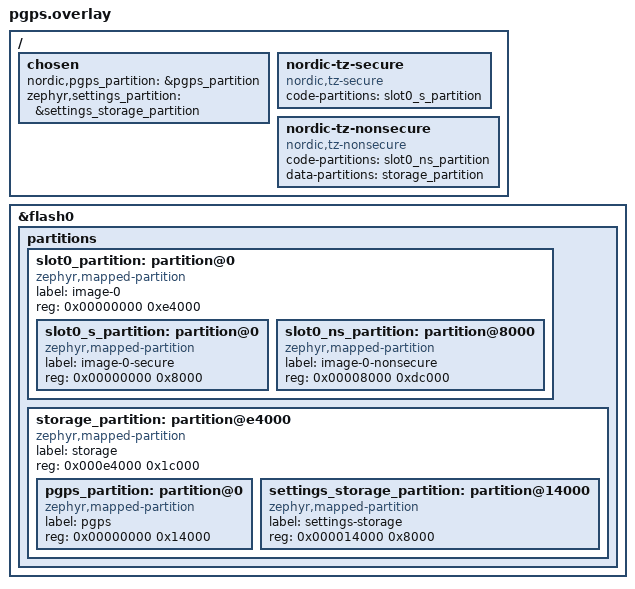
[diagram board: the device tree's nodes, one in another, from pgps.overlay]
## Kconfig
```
#
# Copyright (c) 2020 Nordic Semiconductor ASA
#
# SPDX-License-Identifier: LicenseRef-Nordic-5-Clause
#

menu "GNSS sample"

choice
	default GNSS_SAMPLE_MODE_CONTINUOUS
	prompt "Select GNSS operation mode"

config GNSS_SAMPLE_MODE_CONTINUOUS
	bool "Continuous tracking"

config GNSS_SAMPLE_MODE_PERIODIC
	bool "Periodic fixes"

config GNSS_SAMPLE_MODE_TTFF_TEST
	bool "Time-to-first-fix (TTFF) test mode"
	select GNSS_SAMPLE_NMEA_ONLY

endchoice

if GNSS_SAMPLE_MODE_PERIODIC

config GNSS_SAMPLE_PERIODIC_INTERVAL
	int "Fix interval for periodic fixes"
	range 10 65535
	default 120
	help
	  Fix interval (in seconds) for periodic fixes.

config GNSS_SAMPLE_PERIODIC_TIMEOUT
	int "Fix timeout for periodic fixes"
	range 0 65535
	default 120
	help
	  Fix timeout (in seconds) for periodic fixes.
	  If set to zero, GNSS is allowed to run indefinitely until a valid PVT estimate is produced.

endif # GNSS_SAMPLE_MODE_PERIODIC

if GNSS_SAMPLE_MODE_TTFF_TEST

config GNSS_SAMPLE_MODE_TTFF_TEST_COLD_START
	bool "Delete GNSS data before each start (cold start)"
	help
	  When enabled, deletes all stored data from GNSS to force a cold start every time GNSS is started.

config GNSS_SAMPLE_MODE_TTFF_TEST_INTERVAL
	int "Time to wait between TTFF tests in seconds"
	range 1 604800
	default 120

endif # GNSS_SAMPLE_MODE_TTFF_TEST

config GNSS_SAMPLE_NMEA_ONLY
	bool "Output only NMEA strings"
	help
	  Outputs only NMEA strings from the GNSS.

endmenu

choice
	default GNSS_SAMPLE_ASSISTANCE_NONE
	prompt "Select whether GNSS assistance is used or not"

config GNSS_SAMPLE_ASSISTANCE_NONE
	bool "Assistance not used"

config GNSS_SAMPLE_ASSISTANCE_NRF_CLOUD
	bool "Use nRF Cloud A-GNSS"
	select NRF_CLOUD
	select NRF_CLOUD_COAP
	imply NRF_CLOUD_AGNSS
	select MODEM_JWT
	select MODEM_INFO
	select DATE_TIME

config GNSS_SAMPLE_ASSISTANCE_SUPL
	bool "Use SUPL assistance"
	select SUPL_CLIENT_LIB

config GNSS_SAMPLE_ASSISTANCE_MINIMAL
	bool "Use factory almanac, LTE network time and MCC based location"
	select GNSS_SAMPLE_LTE_ON_DEMAND
	select SETTINGS
	select NVS
	select FLASH
	select FLASH_MAP

endchoice

if !GNSS_SAMPLE_ASSISTANCE_NONE

config GNSS_SAMPLE_LTE_ON_DEMAND
	bool "LTE is activated only when needed to fetch A-GNSS data"
	depends on !NRF_CLOUD_PGPS
	help
	  Activates LTE only when it is needed to fetch A-GNSS data. This is not supported when
	  P-GPS is enabled.

endif # !GNSS_SAMPLE_ASSISTANCE_NONE

if GNSS_SAMPLE_ASSISTANCE_NRF_CLOUD

configdefault COAP_CLIENT_BLOCK_SIZE
	default 1024

configdefault COAP_CLIENT_STACK_SIZE
	default 6144

configdefault COAP_CLIENT_THREAD_PRIORITY
	default 0

endif # GNSS_SAMPLE_ASSISTANCE_NRF_CLOUD

if GNSS_SAMPLE_ASSISTANCE_SUPL

config GNSS_SAMPLE_SUPL_HOSTNAME
	string "SUPL server hostname"
	help
	  SUPL server hostname.

config GNSS_SAMPLE_SUPL_PORT
	int "SUPL server port number"
	range 0 65535
	default 7275 if GNSS_SAMPLE_SUPL_SEC_TAG > 0
	default 7276
	help
	  SUPL server port number. The OMA UserPlane Location Protocol (ULP) port number is 7275,
	  but some servers are known to use port 7276 for non-TLS connections.

config GNSS_SAMPLE_SUPL_SEC_TAG
	int "Security tag for connection to the SUPL server"
	range 0 2147483667
	default 0
	help
	  Set a non-zero value to use TLS for connection to the SUPL server. When TLS is enabled,
	  a root CA certificate must be stored on the modem.

endif # GNSS_SAMPLE_ASSISTANCE_SUPL

if GNSS_SAMPLE_MODE_CONTINUOUS

choice
	default GNSS_SAMPLE_POWER_SAVING_DISABLED
	prompt "Select GNSS power saving mode (duty-cycling)"

config GNSS_SAMPLE_POWER_SAVING_DISABLED
	bool "No power saving"

config GNSS_SAMPLE_POWER_SAVING_MODERATE
	bool "Power saving without significant performance degradation"

config GNSS_SAMPLE_POWER_SAVING_HIGH
	bool "Power saving with acceptable performance degradation"

endchoice

endif # GNSS_SAMPLE_MODE_CONTINUOUS

config GNSS_SAMPLE_REFERENCE_LATITUDE
	string "Reference position latitude in decimal degrees"
	help
	  When set, the sample calculates the distance from the reference position for each fix.
	  Given in decimal degrees (DD), for example "61.500000".

config GNSS_SAMPLE_REFERENCE_LONGITUDE
	string "Reference position longitude in decimal degrees"
	help
	  When set, the sample calculates the distance from the reference position for each fix.
	  Given in decimal degrees (DD), for example "23.800000".

config GNSS_SAMPLE_LOW_ACCURACY
	bool "Allow low accuracy fixes"
	help
	  Allows fixes with lower accuracy.

if GNSS_SAMPLE_ASSISTANCE_MINIMAL && GNSS_SAMPLE_LOW_ACCURACY

config GNSS_SAMPLE_ASSISTANCE_REFERENCE_ALT
	int "Reference altitude for 3-sat first fix in meters"
	range -32767 32767
	default -32767
	help
	  Reference altitude for 3-sat first fix in meters above the reference ellipsoid surface.
	  The default value -32767 implies that reference altitude is not injected.

endif # GNSS_SAMPLE_ASSISTANCE_MINIMAL && GNSS_SAMPLE_LOW_ACCURACY

menu "Zephyr Kernel"
source "Kconfig.zephyr"
endmenu

module = GNSS_SAMPLE
module-str = GNSS sample
source "$(ZEPHYR_BASE)/subsys/logging/Kconfig.template.log_config"
```

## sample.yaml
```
sample:
  name: GNSS sample
tests:
  sample.cellular.gnss:
    sysbuild: true
    build_only: true
    integration_platforms:
      - nrf9151dk/nrf9151/ns
      - nrf9251dk/nrf9251/cpuapp
    platform_allow:
      - nrf9151dk/nrf9151/ns
      - nrf9251dk/nrf9251/cpuapp
    tags:
      - ci_build
      - sysbuild
      - ci_samples_cellular
  # Following configurations will be used by the positioning CI integration job to verify PRs
  sample.cellular.gnss.integration_config_positioning_agnss_nrfcloud_ltem_pvt:
    sysbuild: true
    build_only: true
    extra_configs:
      - CONFIG_LTE_NETWORK_MODE_LTE_M_GPS=y
      - CONFIG_LTE_NETWORK_MODE_NBIOT_GPS=n
      - CONFIG_GNSS_SAMPLE_LTE_ON_DEMAND=y
      - CONFIG_GNSS_SAMPLE_ASSISTANCE_NRF_CLOUD=y
      - CONFIG_GNSS_SAMPLE_NMEA_ONLY=n
      - CONFIG_GNSS_SAMPLE_MODE_PERIODIC=n
      - CONFIG_GNSS_SAMPLE_ASSISTANCE_MINIMAL=n
      - CONFIG_LTE_LC_EDRX_MODULE=y
      - CONFIG_LTE_EDRX_REQ=y
      - CONFIG_FPU=y
      - CONFIG_GNSS_SAMPLE_REFERENCE_LATITUDE="61.49375330"
      - CONFIG_GNSS_SAMPLE_REFERENCE_LONGITUDE="23.77588976"
      - CONFIG_MODEM_ANTENNA_GNSS_EXTERNAL=y
      - CONFIG_LOG_BUFFER_SIZE=2048
    extra_args:
      - gnss_SNIPPET="nrf91-modem-trace-uart"
      - SB_CONFIG_MERGED_HEX_FILES=y
    integration_platforms:
      - nrf9151dk/nrf9151/ns
    platform_allow:
      - nrf9151dk/nrf9151/ns
    tags:
      - ci_build
      - sysbuild
      - ci_samples_cellular
  sample.cellular.gnss.integration_config_positioning_agnss_nrfcloud_nbiot_nmea_lte_on:
    sysbuild: true
    build_only: true
    extra_configs:
      - CONFIG_LTE_NETWORK_MODE_LTE_M_GPS=n
      - CONFIG_LTE_NETWORK_MODE_NBIOT_GPS=y
      - CONFIG_GNSS_SAMPLE_LTE_ON_DEMAND=n
      - CONFIG_GNSS_SAMPLE_ASSISTANCE_NRF_CLOUD=y
      - CONFIG_GNSS_SAMPLE_NMEA_ONLY=y
      - CONFIG_GNSS_SAMPLE_MODE_PERIODIC=n
      - CONFIG_GNSS_SAMPLE_ASSISTANCE_MINIMAL=n
      - CONFIG_LTE_LC_EDRX_MODULE=y
      - CONFIG_LTE_EDRX_REQ=y
      - CONFIG_FPU=y
      - CONFIG_GNSS_SAMPLE_REFERENCE_LATITUDE="61.49375330"
      - CONFIG_GNSS_SAMPLE_REFERENCE_LONGITUDE="23.77588976"
      - CONFIG_MODEM_ANTENNA_GNSS_EXTERNAL=y
      - CONFIG_LOG_BUFFER_SIZE=2048
    extra_args:
      - gnss_SNIPPET="nrf91-modem-trace-uart"
      - SB_CONFIG_MERGED_HEX_FILES=y
    integration_platforms:
      - nrf9151dk/nrf9151/ns
    platform_allow:
      - nrf9151dk/nrf9151/ns
    tags:
      - ci_build
      - sysbuild
      - ci_samples_cellular
  sample.cellular.gnss.integration_config_positioning_pgps_nrfcloud_ltem_nmea:
    sysbuild: true
    build_only: true
    extra_configs:
      - CONFIG_LTE_NETWORK_MODE_LTE_M_GPS=y
      - CONFIG_LTE_NETWORK_MODE_NBIOT_GPS=n
      - CONFIG_GNSS_SAMPLE_LTE_ON_DEMAND=n
      - CONFIG_GNSS_SAMPLE_ASSISTANCE_NRF_CLOUD=n
      - CONFIG_GNSS_SAMPLE_NMEA_ONLY=y
      - CONFIG_GNSS_SAMPLE_MODE_PERIODIC=n
      - CONFIG_GNSS_SAMPLE_ASSISTANCE_MINIMAL=n
      - CONFIG_LTE_EDRX_REQ=n
      - CONFIG_FPU=y
      - CONFIG_GNSS_SAMPLE_REFERENCE_LATITUDE="61.49375330"
      - CONFIG_GNSS_SAMPLE_REFERENCE_LONGITUDE="23.77588976"
      - CONFIG_MODEM_ANTENNA_GNSS_EXTERNAL=y
      - CONFIG_LOG_BUFFER_SIZE=2048
    extra_args:
      - EXTRA_CONF_FILE=pgps.conf
      - EXTRA_DTC_OVERLAY_FILE=pgps.overlay
      - gnss_SNIPPET="nrf91-modem-trace-uart"
      - SB_CONFIG_MERGED_HEX_FILES=y
    integration_platforms:
      - nrf9151dk/nrf9151/ns
    platform_allow:
      - nrf9151dk/nrf9151/ns
    tags:
      - ci_build
      - sysbuild
      - ci_samples_cellular
  sample.cellular.gnss.integration_config_positioning_gnss_ltem_pvt:
    sysbuild: true
    build_only: true
    extra_configs:
      - CONFIG_LTE_NETWORK_MODE_LTE_M_GPS=y
      - CONFIG_LTE_NETWORK_MODE_NBIOT_GPS=n
      - CONFIG_GNSS_SAMPLE_LTE_ON_DEMAND=n
      - CONFIG_GNSS_SAMPLE_ASSISTANCE_NRF_CLOUD=n
      - CONFIG_GNSS_SAMPLE_NMEA_ONLY=n
      - CONFIG_GNSS_SAMPLE_MODE_PERIODIC=n
      - CONFIG_GNSS_SAMPLE_ASSISTANCE_MINIMAL=n
      - CONFIG_LTE_LC_EDRX_MODULE=y
      - CONFIG_LTE_EDRX_REQ=y
      - CONFIG_FPU=y
      - CONFIG_GNSS_SAMPLE_REFERENCE_LATITUDE="61.49375330"
      - CONFIG_GNSS_SAMPLE_REFERENCE_LONGITUDE="23.77588976"
      - CONFIG_MODEM_ANTENNA_GNSS_EXTERNAL=y
      - CONFIG_LOG_BUFFER_SIZE=2048
    extra_args:
      - gnss_SNIPPET="nrf91-modem-trace-uart"
      - SB_CONFIG_MERGED_HEX_FILES=y
    integration_platforms:
      - nrf9151dk/nrf9151/ns
    platform_allow:
      - nrf9151dk/nrf9151/ns
    tags:
      - ci_build
      - sysbuild
      - ci_samples_cellular
```

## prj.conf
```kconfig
#
# Copyright (c) 2019 Nordic Semiconductor ASA
#
# SPDX-License-Identifier: LicenseRef-Nordic-5-Clause
#

# TF-M config
CONFIG_TFM_PROFILE_TYPE_MINIMAL=y

# General
CONFIG_FPU=y
CONFIG_NRF_MODEM_LIB=y
CONFIG_STDOUT_CONSOLE=y
CONFIG_UART_INTERRUPT_DRIVEN=y
CONFIG_PICOLIBC_IO_FLOAT=y
CONFIG_LOG=y
CONFIG_LOG_MODE_IMMEDIATE=y

# GNSS sample
# Enable to use nRF Cloud A-GNSS
CONFIG_GNSS_SAMPLE_ASSISTANCE_NRF_CLOUD=n

# LTE Link Control
CONFIG_LTE_LINK_CONTROL=y
CONFIG_LTE_LC_PSM_MODULE=y
CONFIG_LTE_PSM_REQ=y
# PSM requested periodic TAU 8 hours
CONFIG_LTE_PSM_REQ_RPTAU="00101000"
# PSM requested active time 6 seconds
CONFIG_LTE_PSM_REQ_RAT="00000011"

# AT Host library - Used to send AT commands directy from an UART terminal and to allow
#		    integration with nRF Connect for Desktop LTE Link monitor application.
CONFIG_AT_HOST_LIBRARY=y

# Networking
CONFIG_NETWORKING=y
CONFIG_NET_SOCKETS_OFFLOAD=y
CONFIG_NET_SOCKETS=y
# Disable native network stack to save some memory
CONFIG_NET_NATIVE=n

# Memory and stack configuration
CONFIG_HEAP_MEM_POOL_SIZE=2048
CONFIG_MAIN_STACK_SIZE=4096
CONFIG_SYSTEM_WORKQUEUE_STACK_SIZE=1536
```

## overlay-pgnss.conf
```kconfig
#
# Copyright (c) 2021 Nordic Semiconductor ASA
#
# SPDX-License-Identifier: LicenseRef-Nordic-5-Clause
#

# PGNSS overlay configuration

# Enable nRF Cloud assistance for GNSS sample
CONFIG_GNSS_SAMPLE_ASSISTANCE_NRF_CLOUD=y

# PGNSS
CONFIG_NRF_CLOUD_PGNSS=y
CONFIG_NRF_CLOUD_PGNSS_REPLACEMENT_THRESHOLD=4

# PGNSS downloads over CoAP require larger option values than the default.
CONFIG_COAP_EXTENDED_OPTIONS_LEN_VALUE=80

# Disable A-GNSS, comment this if you want to use both A-GNSS and PGNSS at the same time
CONFIG_NRF_CLOUD_AGNSS=n

# Storage for PGNSS
CONFIG_STREAM_FLASH=y
CONFIG_FLASH=y
CONFIG_FLASH_PAGE_LAYOUT=y
CONFIG_FLASH_MAP=y
CONFIG_FCB=y
CONFIG_SETTINGS=y
CONFIG_SETTINGS_FCB=y
CONFIG_MPU_ALLOW_FLASH_WRITE=y

# PGNSS needs more heap
CONFIG_HEAP_MEM_POOL_SIZE=8192

# Download Client - used by PGNSS
CONFIG_DOWNLOADER=y
CONFIG_DOWNLOADER_STACK_SIZE=1280
CONFIG_DOWNLOADER_MAX_HOSTNAME_SIZE=128
```

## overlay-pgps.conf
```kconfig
#
# Copyright (c) 2021 Nordic Semiconductor ASA
#
# SPDX-License-Identifier: LicenseRef-Nordic-5-Clause
#

# P-GPS overlay configuration

# Enable nRF Cloud assistance for GNSS sample
CONFIG_GNSS_SAMPLE_ASSISTANCE_NRF_CLOUD=y

# P-GPS
CONFIG_NRF_CLOUD_PGPS=y
CONFIG_NRF_CLOUD_PGPS_REPLACEMENT_THRESHOLD=4

# P-GPS downloads over CoAP require larger option values than the default.
CONFIG_COAP_EXTENDED_OPTIONS_LEN_VALUE=80

# Disable A-GNSS, comment this if you want to use both A-GNSS and P-GPS at the same time
CONFIG_NRF_CLOUD_AGNSS=n

# Storage for P-GPS
CONFIG_STREAM_FLASH=y
CONFIG_FLASH=y
CONFIG_FLASH_PAGE_LAYOUT=y
CONFIG_FLASH_MAP=y
CONFIG_FCB=y
CONFIG_SETTINGS=y
CONFIG_SETTINGS_FCB=y
CONFIG_MPU_ALLOW_FLASH_WRITE=y

# P-GPS needs more heap
CONFIG_HEAP_MEM_POOL_SIZE=8192

# Download Client - used by PGPS
CONFIG_DOWNLOADER=y
CONFIG_DOWNLOADER_STACK_SIZE=1280
CONFIG_DOWNLOADER_MAX_HOSTNAME_SIZE=128
```

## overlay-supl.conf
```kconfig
#
# Copyright (c) 2023 Nordic Semiconductor ASA
#
# SPDX-License-Identifier: LicenseRef-Nordic-5-Clause
#

# SUPL overlay configuration

# Enable SUPL assistance for GNSS sample
CONFIG_GNSS_SAMPLE_ASSISTANCE_SUPL=y

# SUPL client library requires that the newlib C library is used
CONFIG_NEWLIB_LIBC=y
CONFIG_NEWLIB_LIBC_FLOAT_PRINTF=y
```

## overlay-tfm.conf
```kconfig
#
# Copyright (c) 2019 Nordic Semiconductor ASA
#
# SPDX-License-Identifier: LicenseRef-Nordic-5-Clause
#

# TF-M config. Only the ``*/ns`` board targets build TF-M, so the TFM_PROFILE
# choice does not exist for board targets that run without it.
CONFIG_TFM_PROFILE_TYPE_MINIMAL=y
```

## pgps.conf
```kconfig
#
# Copyright (c) 2021 Nordic Semiconductor ASA
#
# SPDX-License-Identifier: LicenseRef-Nordic-5-Clause
#

# P-GPS overlay configuration

# Enable nRF Cloud assistance for GNSS sample
CONFIG_GNSS_SAMPLE_ASSISTANCE_NRF_CLOUD=y

# P-GPS
CONFIG_NRF_CLOUD_PGPS=y
CONFIG_NRF_CLOUD_PGPS_REPLACEMENT_THRESHOLD=4

# P-GPS downloads over CoAP require larger option values than the default.
CONFIG_COAP_EXTENDED_OPTIONS_LEN_VALUE=80

# Disable A-GNSS, comment this if you want to use both A-GNSS and P-GPS at the same time
CONFIG_NRF_CLOUD_AGNSS=n

# Storage for P-GPS
CONFIG_STREAM_FLASH=y
CONFIG_FLASH=y
CONFIG_FLASH_MAP=y
CONFIG_NVS=y
CONFIG_NVS_LOG_LEVEL_WRN=y
CONFIG_SETTINGS=y
CONFIG_MPU_ALLOW_FLASH_WRITE=y

# P-GPS needs more heap
CONFIG_HEAP_MEM_POOL_SIZE=8192

# Download Client - used by PGPS
CONFIG_DOWNLOADER=y
CONFIG_DOWNLOADER_STACK_SIZE=1280
CONFIG_DOWNLOADER_MAX_HOSTNAME_SIZE=128
```

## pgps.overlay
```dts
/*
 * Copyright (c) 2026 Nordic Semiconductor ASA
 *
 * SPDX-License-Identifier: LicenseRef-Nordic-5-Clause
 */

/ {
	chosen {
		nordic,pgps_partition = &pgps_partition;
		zephyr,settings_partition = &settings_storage_partition;
	};
};

/delete-node/ &slot0_partition;
/delete-node/ &storage_partition;

&flash0 {
	partitions {
		ranges;
		#address-cells = <1>;
		#size-cells = <1>;

		slot0_partition: partition@0 {
			compatible = "zephyr,mapped-partition";
			label = "image-0";
			reg = <0x00000000 0xe4000>;
			ranges = <0x0 0x00000000 0xe4000>;
			#address-cells = <1>;
			#size-cells = <1>;

			slot0_s_partition: partition@0 {
				compatible = "zephyr,mapped-partition";
				label = "image-0-secure";
				reg = <0x00000000 0x8000>;
			};

			slot0_ns_partition: partition@8000 {
				compatible = "zephyr,mapped-partition";
				label = "image-0-nonsecure";
				reg = <0x00008000 0xdc000>;
			};
		};

		storage_partition: partition@e4000 {
			compatible = "zephyr,mapped-partition";
			label = "storage";
			reg = <0x000e4000 0x1c000>;
			ranges = <0x0 0x000e4000 0x1c000>;
			#address-cells = <1>;
			#size-cells = <1>;

			pgps_partition: partition@0 {
				compatible = "zephyr,mapped-partition";
				label = "pgps";
				reg = <0x00000000 0x14000>;
			};

			settings_storage_partition: partition@14000 {
				compatible = "zephyr,mapped-partition";
				label = "settings-storage";
				reg = <0x000014000 0x8000>;
			};
		};
	};
};

/ {
	/delete-node/ nordic-tz-secure;
	/delete-node/ nordic-tz-nonsecure;

	nordic-tz-secure {
		compatible = "nordic,tz-secure";
		code-partitions = <&slot0_s_partition>;
	};

	nordic-tz-nonsecure {
		compatible = "nordic,tz-nonsecure";
		code-partitions = <&slot0_ns_partition>;
		data-partitions = <&storage_partition>;
	};
};
```

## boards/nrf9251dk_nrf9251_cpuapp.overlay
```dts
/*
 * Copyright (c) 2026 Nordic Semiconductor ASA
 *
 * SPDX-License-Identifier: LicenseRef-Nordic-5-Clause
 */

#include <samples/cellular/nrf92_no_bootloader_partitions.dtsi>

/ {
	chosen {
		ncs,at-host-uart = &uart133;
	};
};
```

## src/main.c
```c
/*
 * Copyright (c) 2019 Nordic Semiconductor ASA
 *
 * SPDX-License-Identifier: LicenseRef-Nordic-5-Clause
 */

#include <stdio.h>
#include <stdlib.h>
#include <string.h>
#include <math.h>
#include <zephyr/kernel.h>
#include <zephyr/logging/log.h>
#include <nrf_modem_at.h>
#include <nrf_modem_gnss.h>
#include <modem/lte_lc.h>
#include <modem/nrf_modem_lib.h>
#include <date_time.h>

LOG_MODULE_REGISTER(gnss_sample, CONFIG_GNSS_SAMPLE_LOG_LEVEL);

#define PI 3.14159265358979323846
#define EARTH_RADIUS_METERS (6371.0 * 1000.0)

#if !defined(CONFIG_GNSS_SAMPLE_ASSISTANCE_NONE) || defined(CONFIG_GNSS_SAMPLE_MODE_TTFF_TEST)
static struct k_work_q gnss_work_q;

#define GNSS_WORKQ_THREAD_STACK_SIZE 2304
#define GNSS_WORKQ_THREAD_PRIORITY   5

K_THREAD_STACK_DEFINE(gnss_workq_stack_area, GNSS_WORKQ_THREAD_STACK_SIZE);
#endif /* !CONFIG_GNSS_SAMPLE_ASSISTANCE_NONE || CONFIG_GNSS_SAMPLE_MODE_TTFF_TEST */

#if !defined(CONFIG_GNSS_SAMPLE_ASSISTANCE_NONE)
#include "assistance.h"

static struct nrf_modem_gnss_agnss_data_frame last_agnss;
static struct k_work agnss_data_get_work;
static volatile bool requesting_assistance;
#endif /* !CONFIG_GNSS_SAMPLE_ASSISTANCE_NONE */

#if defined(CONFIG_GNSS_SAMPLE_MODE_TTFF_TEST)
static struct k_work_delayable ttff_test_got_fix_work;
static struct k_work_delayable ttff_test_prepare_work;
static struct k_work ttff_test_start_work;
static double time_to_fix;
#endif

static const char update_indicator[] = {'\\', '|', '/', '-'};

static struct nrf_modem_gnss_pvt_data_frame last_pvt;
static uint64_t fix_timestamp;
static uint32_t time_blocked;

/* Reference position. */
static bool ref_used;
static double ref_latitude;
static double ref_longitude;

K_MSGQ_DEFINE(nmea_queue, sizeof(struct nrf_modem_gnss_nmea_data_frame *), 15, 4);
static K_SEM_DEFINE(pvt_data_sem, 0, 1);
static K_SEM_DEFINE(time_sem, 0, 1);

static struct k_poll_event events[2] = {
	K_POLL_EVENT_STATIC_INITIALIZER(K_POLL_TYPE_SEM_AVAILABLE,
					K_POLL_MODE_NOTIFY_ONLY,
					&pvt_data_sem, 0),
	K_POLL_EVENT_STATIC_INITIALIZER(K_POLL_TYPE_MSGQ_DATA_AVAILABLE,
					K_POLL_MODE_NOTIFY_ONLY,
					&nmea_queue, 0),
};

BUILD_ASSERT(IS_ENABLED(CONFIG_LTE_NETWORK_MODE_LTE_M_GPS) ||
	     IS_ENABLED(CONFIG_LTE_NETWORK_MODE_NBIOT_GPS) ||
	     IS_ENABLED(CONFIG_LTE_NETWORK_MODE_LTE_M_NBIOT_GPS),
	     "CONFIG_LTE_NETWORK_MODE_LTE_M_GPS, "
	     "CONFIG_LTE_NETWORK_MODE_NBIOT_GPS or "
	     "CONFIG_LTE_NETWORK_MODE_LTE_M_NBIOT_GPS must be enabled");

BUILD_ASSERT((sizeof(CONFIG_GNSS_SAMPLE_REFERENCE_LATITUDE) == 1 &&
	      sizeof(CONFIG_GNSS_SAMPLE_REFERENCE_LONGITUDE) == 1) ||
	     (sizeof(CONFIG_GNSS_SAMPLE_REFERENCE_LATITUDE) > 1 &&
	      sizeof(CONFIG_GNSS_SAMPLE_REFERENCE_LONGITUDE) > 1),
	     "CONFIG_GNSS_SAMPLE_REFERENCE_LATITUDE and "
	     "CONFIG_GNSS_SAMPLE_REFERENCE_LONGITUDE must be both either set or empty");

/* Returns the distance between two coordinates in meters. The distance is calculated using the
 * haversine formula.
 */
static double distance_calculate(double lat1, double lon1,
				 double lat2, double lon2)
{
	double d_lat_rad = (lat2 - lat1) * PI / 180.0;
	double d_lon_rad = (lon2 - lon1) * PI / 180.0;

	double lat1_rad = lat1 * PI / 180.0;
	double lat2_rad = lat2 * PI / 180.0;

	double a = pow(sin(d_lat_rad / 2), 2) +
		   pow(sin(d_lon_rad / 2), 2) *
		   cos(lat1_rad) * cos(lat2_rad);

	double c = 2 * asin(sqrt(a));

	return EARTH_RADIUS_METERS * c;
}

static void print_distance_from_reference(struct nrf_modem_gnss_pvt_data_frame *pvt_data)
{
	if (!ref_used) {
		return;
	}

	double distance = distance_calculate(pvt_data->latitude, pvt_data->longitude,
					     ref_latitude, ref_longitude);

	if (IS_ENABLED(CONFIG_GNSS_SAMPLE_MODE_TTFF_TEST)) {
		LOG_INF("Distance from reference: %.01f", distance);
	} else {
		printf("\nDistance from reference: %.01f\n", distance);
	}
}

static void gnss_event_handler(int event)
{
	int retval;
	struct nrf_modem_gnss_nmea_data_frame *nmea_data;

	switch (event) {
	case NRF_MODEM_GNSS_EVT_PVT:
		retval = nrf_modem_gnss_read(&last_pvt, sizeof(last_pvt), NRF_MODEM_GNSS_DATA_PVT);
		if (retval == 0) {
			k_sem_give(&pvt_data_sem);
		}
		break;

#if defined(CONFIG_GNSS_SAMPLE_MODE_TTFF_TEST)
	case NRF_MODEM_GNSS_EVT_FIX:
		/* Time to fix is calculated here, but it's printed from a delayed work to avoid
		 * messing up the NMEA output.
		 */
		time_to_fix = (k_uptime_get() - fix_timestamp) / 1000.0;
		k_work_schedule_for_queue(&gnss_work_q, &ttff_test_got_fix_work, K_MSEC(100));
		k_work_schedule_for_queue(&gnss_work_q, &ttff_test_prepare_work,
					  K_SECONDS(CONFIG_GNSS_SAMPLE_MODE_TTFF_TEST_INTERVAL));
		break;
#endif /* CONFIG_GNSS_SAMPLE_MODE_TTFF_TEST */

	case NRF_MODEM_GNSS_EVT_NMEA:
		nmea_data = k_malloc(sizeof(struct nrf_modem_gnss_nmea_data_frame));
		if (nmea_data == NULL) {
			LOG_ERR("Failed to allocate memory for NMEA");
			break;
		}

		retval = nrf_modem_gnss_read(nmea_data,
					     sizeof(struct nrf_modem_gnss_nmea_data_frame),
					     NRF_MODEM_GNSS_DATA_NMEA);
		if (retval == 0) {
			retval = k_msgq_put(&nmea_queue, &nmea_data, K_NO_WAIT);
		}

		if (retval != 0) {
			k_free(nmea_data);
		}
		break;

	case NRF_MODEM_GNSS_EVT_AGNSS_REQ:
#if !defined(CONFIG_GNSS_SAMPLE_ASSISTANCE_NONE) && \
	!defined(CONFIG_GNSS_SAMPLE_MODE_TTFF_TEST_COLD_START)
		retval = nrf_modem_gnss_read(&last_agnss,
					     sizeof(last_agnss),
					     NRF_MODEM_GNSS_DATA_AGNSS_REQ);
		if (retval == 0) {
			k_work_submit_to_queue(&gnss_work_q, &agnss_data_get_work);
		}
#endif /* !CONFIG_GNSS_SAMPLE_ASSISTANCE_NONE && !CONFIG_GNSS_SAMPLE_MODE_TTFF_TEST_COLD_START */
		break;

	default:
		break;
	}
}

#if !defined(CONFIG_GNSS_SAMPLE_ASSISTANCE_NONE)
#if defined(CONFIG_GNSS_SAMPLE_LTE_ON_DEMAND)
K_SEM_DEFINE(lte_ready, 0, 1);

static void lte_lc_event_handler(const struct lte_lc_evt *const evt)
{
	switch (evt->type) {
	case LTE_LC_EVT_NW_REG_STATUS:
		if ((evt->nw_reg_status == LTE_LC_NW_REG_REGISTERED_HOME) ||
		    (evt->nw_reg_status == LTE_LC_NW_REG_REGISTERED_ROAMING)) {
			LOG_INF("Connected to LTE network");
			k_sem_give(&lte_ready);
		}
		break;

	default:
		break;
	}
}

void lte_connect(void)
{
	int err;

	LOG_INF("Connecting to LTE network");

	err = lte_lc_func_mode_set(LTE_LC_FUNC_MODE_ACTIVATE_LTE);
	if (err) {
		LOG_ERR("Failed to activate LTE, error: %d", err);
		return;
	}

	k_sem_take(&lte_ready, K_FOREVER);

	/* Wait for a while, because with IPv4v6 PDN the IPv6 activation takes a bit more time. */
	k_sleep(K_SECONDS(1));
}

void lte_disconnect(void)
{
	int err;

	err = lte_lc_func_mode_set(LTE_LC_FUNC_MODE_DEACTIVATE_LTE);
	if (err) {
		LOG_ERR("Failed to deactivate LTE, error: %d", err);
		return;
	}

	LOG_INF("LTE disconnected");
}
#endif /* CONFIG_GNSS_SAMPLE_LTE_ON_DEMAND */

static const char *get_system_string(uint8_t system_id)
{
	switch (system_id) {
	case NRF_MODEM_GNSS_SYSTEM_INVALID:
		return "invalid";

	case NRF_MODEM_GNSS_SYSTEM_GPS:
		return "GPS";

	case NRF_MODEM_GNSS_SYSTEM_QZSS:
		return "QZSS";

	default:
		return "unknown";
	}
}

static void agnss_data_get_work_fn(struct k_work *item)
{
	ARG_UNUSED(item);

	int err;

	/* GPS data need is always expected to be present and first in list. */
	__ASSERT(last_agnss.system_count > 0,
		 "GNSS system data need not found");
	__ASSERT(last_agnss.system[0].system_id == NRF_MODEM_GNSS_SYSTEM_GPS,
		 "GPS data need not found");

#if defined(CONFIG_GNSS_SAMPLE_ASSISTANCE_SUPL)
	/* SUPL doesn't usually provide NeQuick ionospheric corrections and satellite real time
	 * integrity information. If GNSS asks only for those, the request should be ignored.
	 */
	if (last_agnss.system[0].sv_mask_ephe == 0 &&
	    last_agnss.system[0].sv_mask_alm == 0 &&
	    (last_agnss.data_flags & ~(NRF_MODEM_GNSS_AGNSS_NEQUICK_REQUEST |
				       NRF_MODEM_GNSS_AGNSS_INTEGRITY_REQUEST)) == 0) {
		LOG_INF("Ignoring assistance request for only NeQuick and/or integrity");
		return;
	}
#endif /* CONFIG_GNSS_SAMPLE_ASSISTANCE_SUPL */

#if defined(CONFIG_GNSS_SAMPLE_ASSISTANCE_MINIMAL)
	/* With minimal assistance, the request should be ignored if no GPS time or position
	 * is requested.
	 */
	if (!(last_agnss.data_flags & NRF_MODEM_GNSS_AGNSS_GPS_SYS_TIME_AND_SV_TOW_REQUEST) &&
	    !(last_agnss.data_flags & NRF_MODEM_GNSS_AGNSS_POSITION_REQUEST)) {
		LOG_INF("Ignoring assistance request because no GPS time or position is requested");
		return;
	}
#endif /* CONFIG_GNSS_SAMPLE_ASSISTANCE_MINIMAL */

	if (last_agnss.data_flags == 0 &&
	    last_agnss.system[0].sv_mask_ephe == 0 &&
	    last_agnss.system[0].sv_mask_alm == 0) {
		LOG_INF("Ignoring assistance request because only QZSS data is requested");
		return;
	}

	requesting_assistance = true;

	LOG_INF("Assistance data needed: data_flags: 0x%02x", last_agnss.data_flags);
	for (int i = 0; i < last_agnss.system_count; i++) {
		LOG_INF("Assistance data needed: %s ephe: 0x%llx, alm: 0x%llx",
			get_system_string(last_agnss.system[i].system_id),
			last_agnss.system[i].sv_mask_ephe,
			last_agnss.system[i].sv_mask_alm);
	}

#if defined(CONFIG_GNSS_SAMPLE_LTE_ON_DEMAND)
	lte_connect();
#endif /* CONFIG_GNSS_SAMPLE_LTE_ON_DEMAND */

	err = assistance_request(&last_agnss);
	if (err) {
		LOG_ERR("Failed to request assistance data");
	}

#if defined(CONFIG_GNSS_SAMPLE_LTE_ON_DEMAND)
	lte_disconnect();
#endif /* CONFIG_GNSS_SAMPLE_LTE_ON_DEMAND */

	requesting_assistance = false;
}
#endif /* !CONFIG_GNSS_SAMPLE_ASSISTANCE_NONE */

#if defined(CONFIG_GNSS_SAMPLE_MODE_TTFF_TEST)
static void ttff_test_got_fix_work_fn(struct k_work *item)
{
	LOG_INF("Time to fix: %.01f s", time_to_fix);
	if (time_blocked > 0) {
		LOG_INF("Time GNSS was blocked by LTE: %u s", time_blocked);
	}
	print_distance_from_reference(&last_pvt);
	LOG_INF("Sleeping for %u s", CONFIG_GNSS_SAMPLE_MODE_TTFF_TEST_INTERVAL);
}

static int ttff_test_force_cold_start(void)
{
	int err;
	uint32_t delete_mask;

	LOG_INF("Deleting GNSS data");

	/* Delete everything else except the TCXO offset. */
	delete_mask = NRF_MODEM_GNSS_DELETE_EPHEMERIDES |
		      NRF_MODEM_GNSS_DELETE_ALMANACS |
		      NRF_MODEM_GNSS_DELETE_IONO_CORRECTION_DATA |
		      NRF_MODEM_GNSS_DELETE_LAST_GOOD_FIX |
		      NRF_MODEM_GNSS_DELETE_GPS_TOW |
		      NRF_MODEM_GNSS_DELETE_GPS_WEEK |
		      NRF_MODEM_GNSS_DELETE_UTC_DATA |
		      NRF_MODEM_GNSS_DELETE_GPS_TOW_PRECISION;

	/* With minimal assistance, we want to keep the factory almanac. */
	if (IS_ENABLED(CONFIG_GNSS_SAMPLE_ASSISTANCE_MINIMAL)) {
		delete_mask &= ~NRF_MODEM_GNSS_DELETE_ALMANACS;
	}

	err = nrf_modem_gnss_nv_data_delete(delete_mask);
	if (err) {
		LOG_ERR("Failed to delete GNSS data");
		return -1;
	}

	return 0;
}

static void ttff_test_prepare_work_fn(struct k_work *item)
{
	/* Make sure GNSS is stopped before next start. */
	nrf_modem_gnss_stop();

	if (IS_ENABLED(CONFIG_GNSS_SAMPLE_MODE_TTFF_TEST_COLD_START)) {
		if (ttff_test_force_cold_start() != 0) {
			return;
		}
	}

#if !defined(CONFIG_GNSS_SAMPLE_ASSISTANCE_NONE)
	if (IS_ENABLED(CONFIG_GNSS_SAMPLE_MODE_TTFF_TEST_COLD_START)) {
		/* All A-GNSS data is always requested before GNSS is started. */
		last_agnss.data_flags =
			NRF_MODEM_GNSS_AGNSS_GPS_UTC_REQUEST |
			NRF_MODEM_GNSS_AGNSS_KLOBUCHAR_REQUEST |
			NRF_MODEM_GNSS_AGNSS_NEQUICK_REQUEST |
			NRF_MODEM_GNSS_AGNSS_GPS_SYS_TIME_AND_SV_TOW_REQUEST |
			NRF_MODEM_GNSS_AGNSS_POSITION_REQUEST |
			NRF_MODEM_GNSS_AGNSS_INTEGRITY_REQUEST;
		last_agnss.system_count = 1;
		last_agnss.system[0].system_id = NRF_MODEM_GNSS_SYSTEM_GPS;
		last_agnss.system[0].sv_mask_ephe = 0xffffffff;
		last_agnss.system[0].sv_mask_alm = 0xffffffff;
#if defined(CONFIG_GNSS_SAMPLE_ASSISTANCE_NRF_CLOUD)
		last_agnss.system_count = 2;
		last_agnss.system[0].system_id = NRF_MODEM_GNSS_SYSTEM_QZSS;
		last_agnss.system[1].sv_mask_ephe = 0x3ff;
		last_agnss.system[1].sv_mask_alm = 0x3ff;
#endif /* CONFIG_GNSS_SAMPLE_ASSISTANCE_NRF_CLOUD */

		k_work_submit_to_queue(&gnss_work_q, &agnss_data_get_work);
	} else {
		/* Start and stop GNSS to trigger possible A-GNSS data request. If new A-GNSS
		 * data is needed it is fetched before GNSS is started.
		 */
		nrf_modem_gnss_start();
		nrf_modem_gnss_stop();
	}
#endif /* !CONFIG_GNSS_SAMPLE_ASSISTANCE_NONE */

	k_work_submit_to_queue(&gnss_work_q, &ttff_test_start_work);
}

static void ttff_test_start_work_fn(struct k_work *item)
{
	LOG_INF("Starting GNSS");
	if (nrf_modem_gnss_start() != 0) {
		LOG_ERR("Failed to start GNSS");
		return;
	}

	fix_timestamp = k_uptime_get();
	time_blocked = 0;
}
#endif /* CONFIG_GNSS_SAMPLE_MODE_TTFF_TEST */

static void date_time_evt_handler(const struct date_time_evt *evt)
{
	k_sem_give(&time_sem);
}

static int modem_init(void)
{
	if (IS_ENABLED(CONFIG_DATE_TIME)) {
		date_time_register_handler(date_time_evt_handler);
	}

#if defined(CONFIG_GNSS_SAMPLE_LTE_ON_DEMAND)
	lte_lc_register_handler(lte_lc_event_handler);
#elif !defined(CONFIG_GNSS_SAMPLE_ASSISTANCE_NONE)
	LOG_INF("Connecting to LTE network");

	if (lte_lc_connect() != 0) {
		LOG_ERR("Failed to connect to LTE network");
		return -1;
	}

	LOG_INF("Connected to LTE network");

	if (IS_ENABLED(CONFIG_DATE_TIME)) {
		LOG_INF("Waiting for current time");

		/* Wait for an event from the Date Time library. */
		k_sem_take(&time_sem, K_MINUTES(10));

		if (!date_time_is_valid()) {
			LOG_WRN("Failed to get current time, continuing anyway");
		}
	}
#endif

	return 0;
}

static int sample_init(void)
{
	int err = 0;

#if !defined(CONFIG_GNSS_SAMPLE_ASSISTANCE_NONE) || defined(CONFIG_GNSS_SAMPLE_MODE_TTFF_TEST)
	struct k_work_queue_config cfg = {
		.name = "gnss_work_q",
		.no_yield = false
	};

	k_work_queue_start(
		&gnss_work_q,
		gnss_workq_stack_area,
		K_THREAD_STACK_SIZEOF(gnss_workq_stack_area),
		GNSS_WORKQ_THREAD_PRIORITY,
		&cfg);
#endif /* !CONFIG_GNSS_SAMPLE_ASSISTANCE_NONE || CONFIG_GNSS_SAMPLE_MODE_TTFF_TEST */

#if !defined(CONFIG_GNSS_SAMPLE_ASSISTANCE_NONE)
	k_work_init(&agnss_data_get_work, agnss_data_get_work_fn);

	err = assistance_init(&gnss_work_q);
#endif /* !CONFIG_GNSS_SAMPLE_ASSISTANCE_NONE */

#if defined(CONFIG_GNSS_SAMPLE_MODE_TTFF_TEST)
	k_work_init_delayable(&ttff_test_got_fix_work, ttff_test_got_fix_work_fn);
	k_work_init_delayable(&ttff_test_prepare_work, ttff_test_prepare_work_fn);
	k_work_init(&ttff_test_start_work, ttff_test_start_work_fn);
#endif /* CONFIG_GNSS_SAMPLE_MODE_TTFF_TEST */

	return err;
}

static int gnss_init_and_start(void)
{
#if defined(CONFIG_GNSS_SAMPLE_ASSISTANCE_NONE) || defined(CONFIG_GNSS_SAMPLE_LTE_ON_DEMAND)
	/* Enable GNSS. */
	if (lte_lc_func_mode_set(LTE_LC_FUNC_MODE_ACTIVATE_GNSS) != 0) {
		LOG_ERR("Failed to activate GNSS functional mode");
		return -1;
	}
#endif /* CONFIG_GNSS_SAMPLE_ASSISTANCE_NONE || CONFIG_GNSS_SAMPLE_LTE_ON_DEMAND */

	/* Configure GNSS. */
	if (nrf_modem_gnss_event_handler_set(gnss_event_handler) != 0) {
		LOG_ERR("Failed to set GNSS event handler");
		return -1;
	}

	/* Enable all supported NMEA messages. */
	uint16_t nmea_mask = NRF_MODEM_GNSS_NMEA_RMC_MASK |
			     NRF_MODEM_GNSS_NMEA_GGA_MASK |
			     NRF_MODEM_GNSS_NMEA_GLL_MASK |
			     NRF_MODEM_GNSS_NMEA_GSA_MASK |
			     NRF_MODEM_GNSS_NMEA_GSV_MASK;

	if (nrf_modem_gnss_nmea_mask_set(nmea_mask) != 0) {
		LOG_ERR("Failed to set GNSS NMEA mask");
		return -1;
	}

	/* Make QZSS satellites visible in the NMEA output. */
	if (nrf_modem_gnss_qzss_nmea_mode_set(NRF_MODEM_GNSS_QZSS_NMEA_MODE_CUSTOM) != 0) {
		LOG_WRN("Failed to enable custom QZSS NMEA mode");
	}

	/* This use case flag should always be set. */
	uint8_t use_case = NRF_MODEM_GNSS_USE_CASE_MULTIPLE_HOT_START;

	if (IS_ENABLED(CONFIG_GNSS_SAMPLE_MODE_PERIODIC) &&
	    !IS_ENABLED(CONFIG_GNSS_SAMPLE_ASSISTANCE_NONE)) {
		/* Disable GNSS scheduled downloads when assistance is used. */
		use_case |= NRF_MODEM_GNSS_USE_CASE_SCHED_DOWNLOAD_DISABLE;
	}

	if (IS_ENABLED(CONFIG_GNSS_SAMPLE_LOW_ACCURACY)) {
		use_case |= NRF_MODEM_GNSS_USE_CASE_LOW_ACCURACY;
	}

	if (nrf_modem_gnss_use_case_set(use_case) != 0) {
		LOG_WRN("Failed to set GNSS use case");
	}

#if defined(CONFIG_NRF_CLOUD_AGNSS_ELEVATION_MASK)
	if (nrf_modem_gnss_elevation_threshold_set(CONFIG_NRF_CLOUD_AGNSS_ELEVATION_MASK) != 0) {
		LOG_ERR("Failed to set elevation threshold");
		return -1;
	}
	LOG_DBG("Set elevation threshold to %u", CONFIG_NRF_CLOUD_AGNSS_ELEVATION_MASK);
#endif

#if defined(CONFIG_GNSS_SAMPLE_MODE_CONTINUOUS)
	/* Default to no power saving. */
	uint8_t power_mode = NRF_MODEM_GNSS_PSM_DISABLED;

#if defined(CONFIG_GNSS_SAMPLE_POWER_SAVING_MODERATE)
	power_mode = NRF_MODEM_GNSS_PSM_DUTY_CYCLING_PERFORMANCE;
#elif defined(CONFIG_GNSS_SAMPLE_POWER_SAVING_HIGH)
	power_mode = NRF_MODEM_GNSS_PSM_DUTY_CYCLING_POWER;
#endif

	if (nrf_modem_gnss_power_mode_set(power_mode) != 0) {
		LOG_ERR("Failed to set GNSS power saving mode");
		return -1;
	}
#endif /* CONFIG_GNSS_SAMPLE_MODE_CONTINUOUS */

	/* Default to continuous tracking. */
	uint16_t fix_retry = 0;
	uint16_t fix_interval = 1;

#if defined(CONFIG_GNSS_SAMPLE_MODE_PERIODIC)
	fix_retry = CONFIG_GNSS_SAMPLE_PERIODIC_TIMEOUT;
	fix_interval = CONFIG_GNSS_SAMPLE_PERIODIC_INTERVAL;
#elif defined(CONFIG_GNSS_SAMPLE_MODE_TTFF_TEST)
	/* Single fix for TTFF test mode. */
	fix_retry = 0;
	fix_interval = 0;
#endif

	if (nrf_modem_gnss_fix_retry_set(fix_retry) != 0) {
		LOG_ERR("Failed to set GNSS fix retry");
		return -1;
	}

	if (nrf_modem_gnss_fix_interval_set(fix_interval) != 0) {
		LOG_ERR("Failed to set GNSS fix interval");
		return -1;
	}

#if defined(CONFIG_GNSS_SAMPLE_MODE_TTFF_TEST)
	k_work_schedule_for_queue(&gnss_work_q, &ttff_test_prepare_work, K_NO_WAIT);
#else /* !CONFIG_GNSS_SAMPLE_MODE_TTFF_TEST */
	if (nrf_modem_gnss_start() != 0) {
		LOG_ERR("Failed to start GNSS");
		return -1;
	}
#endif

	return 0;
}

static bool output_paused(void)
{
#if defined(CONFIG_GNSS_SAMPLE_ASSISTANCE_NONE) || defined(CONFIG_GNSS_SAMPLE_LOG_LEVEL_OFF)
	return false;
#else
	return (requesting_assistance || assistance_is_active()) ? true : false;
#endif
}

static void print_satellite_stats(struct nrf_modem_gnss_pvt_data_frame *pvt_data)
{
	uint8_t tracked   = 0;
	uint8_t in_fix    = 0;
	uint8_t unhealthy = 0;

	for (int i = 0; i < NRF_MODEM_GNSS_MAX_SATELLITES; ++i) {
		if (pvt_data->sv[i].sv > 0) {
			tracked++;

			if (pvt_data->sv[i].flags & NRF_MODEM_GNSS_SV_FLAG_USED_IN_FIX) {
				in_fix++;
			}

			if (pvt_data->sv[i].flags & NRF_MODEM_GNSS_SV_FLAG_UNHEALTHY) {
				unhealthy++;
			}
		}
	}

	printf("Tracking: %2d Using: %2d Unhealthy: %d\n", tracked, in_fix, unhealthy);
}

static void print_flags(struct nrf_modem_gnss_pvt_data_frame *pvt_data)
{
	if (pvt_data->flags & NRF_MODEM_GNSS_PVT_FLAG_DEADLINE_MISSED) {
		printf("GNSS operation blocked by LTE\n");
	}
	if (pvt_data->flags & NRF_MODEM_GNSS_PVT_FLAG_NOT_ENOUGH_WINDOW_TIME) {
		printf("Insufficient GNSS time windows\n");
	}
	if (pvt_data->flags & NRF_MODEM_GNSS_PVT_FLAG_SLEEP_BETWEEN_PVT) {
		printf("Sleep period(s) between PVT notifications\n");
	}
	if (pvt_data->flags & NRF_MODEM_GNSS_PVT_FLAG_SCHED_DOWNLOAD) {
		printf("Scheduled navigation data download\n");
	}
}

static void print_fix_data(struct nrf_modem_gnss_pvt_data_frame *pvt_data)
{
	printf("Latitude:          %.06f\n", pvt_data->latitude);
	printf("Longitude:         %.06f\n", pvt_data->longitude);
	printf("Accuracy:          %.01f m\n", (double)pvt_data->accuracy);
	printf("Altitude:          %.01f m\n", (double)pvt_data->altitude);
	printf("Altitude accuracy: %.01f m\n", (double)pvt_data->altitude_accuracy);
	printf("Speed:             %.01f m/s\n", (double)pvt_data->speed);
	printf("Speed accuracy:    %.01f m/s\n", (double)pvt_data->speed_accuracy);
	printf("V. speed:          %.01f m/s\n", (double)pvt_data->vertical_speed);
	printf("V. speed accuracy: %.01f m/s\n", (double)pvt_data->vertical_speed_accuracy);
	printf("Heading:           %.01f deg\n", (double)pvt_data->heading);
	printf("Heading accuracy:  %.01f deg\n", (double)pvt_data->heading_accuracy);
	printf("Date:              %04u-%02u-%02u\n",
	       pvt_data->datetime.year,
	       pvt_data->datetime.month,
	       pvt_data->datetime.day);
	printf("Time (UTC):        %02u:%02u:%02u.%03u\n",
	       pvt_data->datetime.hour,
	       pvt_data->datetime.minute,
	       pvt_data->datetime.seconds,
	       pvt_data->datetime.ms);
	printf("PDOP:              %.01f\n", (double)pvt_data->pdop);
	printf("HDOP:              %.01f\n", (double)pvt_data->hdop);
	printf("VDOP:              %.01f\n", (double)pvt_data->vdop);
	printf("TDOP:              %.01f\n", (double)pvt_data->tdop);
}

int main(void)
{
	int err;
	uint8_t cnt = 0;
	struct nrf_modem_gnss_nmea_data_frame *nmea_data;

	LOG_INF("Starting GNSS sample");

	err = nrf_modem_lib_init();
	if (err) {
		LOG_ERR("Modem library initialization failed, error: %d", err);
		return err;
	}

	/* Initialize reference coordinates (if used). */
	if (sizeof(CONFIG_GNSS_SAMPLE_REFERENCE_LATITUDE) > 1 &&
	    sizeof(CONFIG_GNSS_SAMPLE_REFERENCE_LONGITUDE) > 1) {
		ref_used = true;
		ref_latitude = atof(CONFIG_GNSS_SAMPLE_REFERENCE_LATITUDE);
		ref_longitude = atof(CONFIG_GNSS_SAMPLE_REFERENCE_LONGITUDE);
	}

	if (modem_init() != 0) {
		LOG_ERR("Failed to initialize modem");
		return -1;
	}

	if (sample_init() != 0) {
		LOG_ERR("Failed to initialize sample");
		return -1;
	}

	if (gnss_init_and_start() != 0) {
		LOG_ERR("Failed to initialize and start GNSS");
		return -1;
	}

	fix_timestamp = k_uptime_get();

	for (;;) {
		(void)k_poll(events, 2, K_FOREVER);

		if (events[0].state == K_POLL_STATE_SEM_AVAILABLE &&
		    k_sem_take(events[0].sem, K_NO_WAIT) == 0) {
			/* New PVT data available */

			if (IS_ENABLED(CONFIG_GNSS_SAMPLE_MODE_TTFF_TEST)) {
				/* TTFF test mode. */

				/* Calculate the time GNSS has been blocked by LTE. */
				if (last_pvt.flags & NRF_MODEM_GNSS_PVT_FLAG_DEADLINE_MISSED) {
					time_blocked++;
				}
			} else if (IS_ENABLED(CONFIG_GNSS_SAMPLE_NMEA_ONLY)) {
				/* NMEA-only output mode. */

				if (output_paused()) {
					goto handle_nmea;
				}

				if (last_pvt.flags & NRF_MODEM_GNSS_PVT_FLAG_FIX_VALID) {
					print_distance_from_reference(&last_pvt);
				}
			} else {
				/* PVT and NMEA output mode. */

				if (output_paused()) {
					goto handle_nmea;
				}

				printf("\033[1;1H");
				printf("\033[2J");
				print_satellite_stats(&last_pvt);
				print_flags(&last_pvt);
				printf("-----------------------------------\n");

				if (last_pvt.flags & NRF_MODEM_GNSS_PVT_FLAG_FIX_VALID) {
					fix_timestamp = k_uptime_get();
					print_fix_data(&last_pvt);
					print_distance_from_reference(&last_pvt);
				} else {
					printf("Seconds since last fix: %d\n",
					       (uint32_t)((k_uptime_get() - fix_timestamp) / 1000));
					cnt++;
					printf("Searching [%c]\n", update_indicator[cnt%4]);
				}

				printf("\nNMEA strings:\n\n");
			}
		}

handle_nmea:
		if (events[1].state == K_POLL_STATE_MSGQ_DATA_AVAILABLE &&
		    k_msgq_get(events[1].msgq, &nmea_data, K_NO_WAIT) == 0) {
			/* New NMEA data available */

			if (!output_paused()) {
				printf("%s", nmea_data->nmea_str);
			}
			k_free(nmea_data);
		}

		events[0].state = K_POLL_STATE_NOT_READY;
		events[1].state = K_POLL_STATE_NOT_READY;
	}

	return 0;
}
```

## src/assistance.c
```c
/*
 * Copyright (c) 2021 Nordic Semiconductor ASA
 *
 * SPDX-License-Identifier: LicenseRef-Nordic-5-Clause
 */

#include <stdlib.h>
#include <zephyr/kernel.h>
#include <zephyr/logging/log.h>
#include <modem/modem_info.h>
#if defined(CONFIG_NRF_CLOUD_AGNSS)
#include <net/nrf_cloud_agnss.h>
#endif /* CONFIG_NRF_CLOUD_AGNSS */
#if defined(CONFIG_NRF_CLOUD_PGNSS)
#include <net/nrf_cloud_pgnss.h>
#endif /* CONFIG_NRF_CLOUD_PGNSS */
#include <net/nrf_cloud_coap.h>

#include "assistance.h"

LOG_MODULE_DECLARE(gnss_sample, CONFIG_GNSS_SAMPLE_LOG_LEVEL);

#if defined(CONFIG_NRF_CLOUD_AGNSS)
static char agnss_data_buf[NRF_CLOUD_AGNSS_MAX_DATA_SIZE];
#endif /* CONFIG_NRF_CLOUD_AGNSS */

#if defined(CONFIG_NRF_CLOUD_PGNSS)
static struct nrf_modem_gnss_agnss_data_frame agnss_need;
static struct gps_pgnss_request pgnss_request;
static struct nrf_cloud_pgnss_prediction *prediction;
static struct k_work get_pgnss_data_work;
static struct k_work inject_pgnss_data_work;
#endif /* CONFIG_NRF_CLOUD_PGNSS */

static struct k_work_q *work_q;
static volatile bool assistance_active;
static bool coap_connected;

#if defined(CONFIG_NRF_CLOUD_AGNSS)
static int serving_cell_info_get(struct lte_lc_cell *serving_cell)
{
	int err;

	err = modem_info_init();
	if (err) {
		return err;
	}

	char resp_buf[MODEM_INFO_MAX_RESPONSE_SIZE];

	err = modem_info_string_get(MODEM_INFO_CELLID,
				    resp_buf,
				    MODEM_INFO_MAX_RESPONSE_SIZE);
	if (err < 0) {
		return err;
	}

	serving_cell->id = strtol(resp_buf, NULL, 16);

	err = modem_info_string_get(MODEM_INFO_AREA_CODE,
				    resp_buf,
				    MODEM_INFO_MAX_RESPONSE_SIZE);
	if (err < 0) {
		return err;
	}

	serving_cell->tac = strtol(resp_buf, NULL, 16);

	/* Request for MODEM_INFO_MNC returns both MNC and MCC in the same string. */
	err = modem_info_string_get(MODEM_INFO_OPERATOR,
				    resp_buf,
				    MODEM_INFO_MAX_RESPONSE_SIZE);
	if (err < 0) {
		return err;
	}

	serving_cell->mnc = strtol(&resp_buf[3], NULL, 10);
	/* Null-terminate MCC, read and store it. */
	resp_buf[3] = '\0';
	serving_cell->mcc = strtol(resp_buf, NULL, 10);

	return 0;
}
#endif /* CONFIG_NRF_CLOUD_AGNSS */

#if defined(CONFIG_NRF_CLOUD_PGNSS)
static void get_pgnss_data_work_fn(struct k_work *work)
{
	ARG_UNUSED(work);

	int err;

	assistance_active = true;

	LOG_INF("Sending request for PGNSS predictions to nRF Cloud...");

	struct nrf_cloud_coap_pgnss_request request = {
		.pgnss_req = &pgnss_request
	};

	struct nrf_cloud_pgnss_result file_location = {0};

	static char host[64];
	static char path[128];

	memset(host, 0, sizeof(host));
	memset(path, 0, sizeof(path));

	file_location.host = host;
	file_location.host_sz = sizeof(host);
	file_location.path = path;
	file_location.path_sz = sizeof(path);

	err = nrf_cloud_coap_pgnss_url_get(&request, &file_location);
	if (err) {
		LOG_ERR("GNSS: Failed to get PGNSS data, error: %d", err);

		nrf_cloud_pgnss_request_reset();

		goto exit;
	}

	LOG_INF("Processing PGNSS response");

	err = nrf_cloud_pgnss_update(&file_location);
	if (err) {
		LOG_ERR("Failed to process PGNSS response, error: %d", err);

		nrf_cloud_pgnss_request_reset();

		goto exit;
	}

	LOG_INF("PGNSS response processed");

	err = nrf_cloud_pgnss_notify_prediction();
	if (err) {
		LOG_ERR("Failed to request current prediction, error: %d", err);

		goto exit;
	}

	LOG_INF("PGNSS predictions requested");
exit:
	assistance_active = false;
}

static void inject_pgnss_data_work_fn(struct k_work *work)
{
	ARG_UNUSED(work);

	int err;

	assistance_active = true;

	LOG_INF("Injecting PGNSS ephemerides");

	err = nrf_cloud_pgnss_inject(prediction, &agnss_need);
	if (err) {
		LOG_ERR("Failed to inject PGNSS ephemerides");
	}

	err = nrf_cloud_pgnss_preemptive_updates();
	if (err) {
		LOG_ERR("Failed to request PGNSS updates");
	}

	assistance_active = false;
}

static void pgnss_event_handler(struct nrf_cloud_pgnss_event *event)
{
	switch (event->type) {
	case PGNSS_EVT_AVAILABLE:
		prediction = event->prediction;

		k_work_submit_to_queue(work_q, &inject_pgnss_data_work);
		break;

	case PGNSS_EVT_REQUEST:
		memcpy(&pgnss_request, event->request, sizeof(pgnss_request));

		k_work_submit_to_queue(work_q, &get_pgnss_data_work);
		break;

	case PGNSS_EVT_LOADING:
		LOG_INF("Loading PGNSS predictions");
		assistance_active = true;
		break;

	case PGNSS_EVT_READY:
		LOG_INF("PGNSS predictions ready");
		assistance_active = false;
		break;

	default:
		/* No action needed */
		break;
	}
}
#endif /* CONFIG_NRF_CLOUD_PGNSS */

#if defined(CONFIG_NRF_CLOUD_AGNSS)
static const char *get_system_string(uint8_t system_id)
{
	switch (system_id) {
	case NRF_MODEM_GNSS_SYSTEM_INVALID:
		return "invalid";

	case NRF_MODEM_GNSS_SYSTEM_GPS:
		return "GPS";

	case NRF_MODEM_GNSS_SYSTEM_QZSS:
		return "QZSS";

	default:
		return "unknown";
	}
}
#endif /* CONFIG_NRF_CLOUD_AGNSS */

int assistance_init(struct k_work_q *assistance_work_q)
{
	work_q = assistance_work_q;

	int err = nrf_cloud_coap_init();

	if (err) {
		LOG_ERR("Failed to initialize nRF Cloud CoAP client: %d", err);
		return err;
	}

#if defined(CONFIG_NRF_CLOUD_PGNSS)
	k_work_init(&get_pgnss_data_work, get_pgnss_data_work_fn);
	k_work_init(&inject_pgnss_data_work, inject_pgnss_data_work_fn);

	struct nrf_cloud_pgnss_init_param pgnss_param = {
		.event_handler = pgnss_event_handler,
		/* storage is defined by CONFIG_NRF_CLOUD_PGNSS_STORAGE */
		.storage_base = 0u,
		.storage_size = 0u
	};

	if (nrf_cloud_pgnss_init(&pgnss_param) != 0) {
		LOG_ERR("Failed to initialize PGNSS");
		return -1;
	}
#endif /* CONFIG_NRF_CLOUD_PGNSS */

	return 0;
}

int assistance_request(struct nrf_modem_gnss_agnss_data_frame *agnss_request)
{
	int err = 0;

	if (!coap_connected) {
		err = nrf_cloud_coap_connect(NULL);
		if (err) {
			LOG_ERR("Connecting to nRF Cloud failed: %d", err);
			return err;
		}
		coap_connected = true;
	}

#if defined(CONFIG_NRF_CLOUD_PGNSS)
	/* Store the A-GNSS data request for PGNSS use. */
	memcpy(&agnss_need, agnss_request, sizeof(agnss_need));

#if defined(CONFIG_NRF_CLOUD_AGNSS)
	if (!agnss_request->data_flags) {
		/* No assistance needed from A-GNSS, skip directly to PGNSS. */
		nrf_cloud_pgnss_notify_prediction();
		return 0;
	}

	/* PGNSS will handle GPS ephemerides, so skip those. */
	agnss_request->system[0].sv_mask_ephe = 0;
	/* GPS almanacs are not needed with PGNSS, so skip those. */
	agnss_request->system[0].sv_mask_alm = 0;
#endif /* CONFIG_NRF_CLOUD_AGNSS */
#endif /* CONFIG_NRF_CLOUD_PGNSS */
#if defined(CONFIG_NRF_CLOUD_AGNSS)
	assistance_active = true;

	struct nrf_cloud_coap_agnss_request request = {
		NRF_CLOUD_COAP_AGNSS_REQ_CUSTOM,
		agnss_request,
		NULL,
#if defined(CONFIG_NRF_CLOUD_AGNSS_FILTERED_RUNTIME)
		true,
		/* Note: if you change the mask angle here, you may want to
		 * also change it to match in gnss_init_and_start() in main.c.
		 */
		CONFIG_NRF_CLOUD_AGNSS_ELEVATION_MASK
#endif
	};

	struct nrf_cloud_coap_agnss_result result = {
		agnss_data_buf,
		sizeof(agnss_data_buf),
		0
	};

	struct lte_lc_cells_info net_info = { 0 };

	err = serving_cell_info_get(&net_info.current_cell);
	if (err) {
		LOG_ERR("Could not get cell info, error: %d", err);
	} else {
		/* Network info for the location request. */
		request.net_info = &net_info;
	}

	LOG_INF("Requesting A-GNSS data: data_flags: 0x%02x", agnss_request->data_flags);
	for (int i = 0; i < agnss_request->system_count; i++) {
		LOG_INF("Requesting A-GNSS data: %s ephe: 0x%llx, alm: 0x%llx",
			get_system_string(agnss_request->system[i].system_id),
			agnss_request->system[i].sv_mask_ephe,
			agnss_request->system[i].sv_mask_alm);
	}

	err = nrf_cloud_coap_agnss_data_get(&request, &result);
	if (err) {
		LOG_ERR("Failed to get A-GNSS data, error: %d", err);
		goto agnss_exit;
	}

	LOG_INF("Processing A-GNSS data");

	err = nrf_cloud_agnss_process(result.buf, result.agnss_sz);
	if (err) {
		LOG_ERR("Failed to process A-GNSS data, error: %d", err);
		goto agnss_exit;
	}

	LOG_INF("A-GNSS data processed");

agnss_exit:
	assistance_active = false;
#endif /* CONFIG_NRF_CLOUD_AGNSS */

#if defined(CONFIG_NRF_CLOUD_PGNSS)
	nrf_cloud_pgnss_notify_prediction();
#endif /* CONFIG_NRF_CLOUD_PGNSS */

	return err;
}

bool assistance_is_active(void)
{
	return assistance_active;
}
```

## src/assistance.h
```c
/*
 * Copyright (c) 2019 Nordic Semiconductor ASA
 *
 * SPDX-License-Identifier: LicenseRef-Nordic-5-Clause
 */

#ifndef ASSISTANCE_H_
#define ASSISTANCE_H_

#ifdef __cplusplus
extern "C" {
#endif

/**
 * @brief Initializes the assistance module.
 *
 * @param[in] assistance_work_q Work queue that can be used by the assistance module.
 *
 * @retval 0 on success.
 * @retval -1 in case of an error.
 */
int assistance_init(struct k_work_q *assistance_work_q);

/**
 * @brief Handles an assistance data request.
 *
 * @details Fetches and injects assistance data to the GNSS.
 *
 * @param[in] agnss_request A-GNSS data requested by GNSS.
 *
 * @retval 0 on success.
 * @retval <0 in case of an error.
 */
int assistance_request(struct nrf_modem_gnss_agnss_data_frame *agnss_request);

/**
 * @brief Returns assistance module state.
 *
 * @retval true if assistance module is downloading data.
 * @retval false if assistance module is idle.
 */
bool assistance_is_active(void);

#ifdef __cplusplus
}
#endif

#endif /* ASSISTANCE_H_ */
```

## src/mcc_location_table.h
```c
/*
 * Copyright (c) 2021 Nordic Semiconductor ASA
 *
 * SPDX-License-Identifier: LicenseRef-Nordic-5-Clause
 */

#ifndef MCC_LOCATION_TABLE_H_
#define MCC_LOCATION_TABLE_H_

struct __attribute__ ((__packed__)) mcc_table {
	uint8_t confidence;    /* percentage, 0-100 */
	uint8_t unc_semiminor; /* scaled, see GNSS interface for details */
	uint8_t unc_semimajor; /* scaled, see GNSS interface for details */
	uint8_t orientation;   /* orientation angle between the major axis and north */
	float lat;
	float lon;
	uint16_t mcc;
};

/**
 * @brief Finds location information for a given Mobile Country Code (MCC).
 *
 * @param mcc[in] MCC to look for.
 *
 * @return Location information for the matching MCC, NULL if no entry was found.
 */
const struct mcc_table *mcc_lookup(uint16_t mcc);

/**
 * @brief Converts a latitude in degrees to the integer representation used by GNSS.
 *
 * @param lat[in] Latitude in degrees.
 *
 * @return Latitude in scaled integer representation.
 */
int32_t lat_convert(float lat);

/**
 * @brief Converts a longitude in degrees to the integer representation used by GNSS.
 *
 * @param lon[in] Longitude in degrees.
 *
 * @return Longitude in scaled integer representation.
 */
int32_t lon_convert(float lon);

#endif /* MCC_LOCATION_TABLE_H_ */
```
